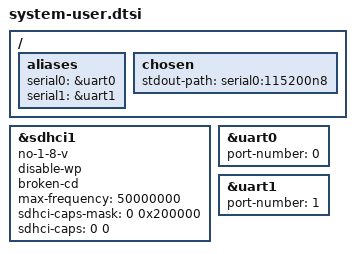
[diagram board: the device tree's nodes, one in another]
// SPDX-License-Identifier: MIT
// Copyright (C) 2025-2026, Opsero Electronic Design Inc.  All rights reserved.

/*
 * SoC-side board fixups for zcu104 (ZynqMP), layered on top of the
 * gen-machineconf / lopper-generated Linux device tree (which already carries
 * the PS config and the design's PL hardware from the XSA). Scoped to the Linux
 * domain by device-tree.bbappend. Ported from the Ethernet FMC Zynq GEM PetaLinux BSP.
 */

/* The Vivado design for this repo exports a minimal sdhci1 node (just
 * clock-frequency, status, mio-bank). Without these extra properties
 * Linux times out initialising the SD card with "error -110". Values
 * mirror what the stock 2025.2 xilinx-zcu104 BSP uses. */
&sdhci1 {
   no-1-8-v;
   disable-wp;
   broken-cd;
   max-frequency = <50000000>;
   /* Cap SDR50/HS modes — these bits in SDHCI_CAPABILITIES block faster UHS
    * modes that the ZCU104 level shifter can't sustain. */
   sdhci-caps-mask = <0 0x200000>;
   sdhci-caps = <0 0>;
};

/* 2025.2 gen-machineconf assigns port-number=0 to uart1, making ttyPS0 map
 * to uart1. Vitis bsp.yaml confirms this board uses psu_uart_0, so force
 * ttyPS0 back to uart0. */
&uart0 {
   port-number = <0>;
};
&uart1 {
   port-number = <1>;
};
/ {
   aliases {
      serial0 = &uart0;
      serial1 = &uart1;
   };
   chosen {
      stdout-path = "serial0:115200n8";
   };
};
